# CY8C4248LQI_BL583 register map
File version: 0.1
PSoC 4200 BLE
Registers are 32-bit, read-write, no defined reset value unless marked. A register's access mark holds for its fields unless they carry their own. Offsets are from the block's base; lines under a group give offsets from that group; [hi:lo] are bit positions; {n}, {i} and the like mark numbered series; 'fields as' and 'values as' point back to an identical list; <NAME> marks a mode.

## Memory map
0x00000000 DMAC — DMAC Registers
0x00000000 FanController
0x00000000 FanController_FW_PWM1
0x00000000 FanController_FW_PWM3
0x00000000 FanController_FW_PWM2
0x00000000 FanController_FW_PWM4
0x00000000 UART — Serial Communication Block
0x00000000 Control_Rotation

## FanController
Base 0x00000000
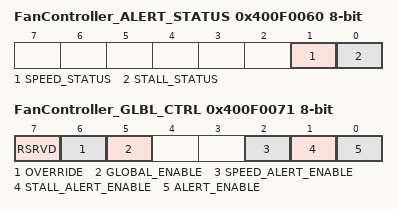
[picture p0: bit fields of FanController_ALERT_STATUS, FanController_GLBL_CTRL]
0x400F0060 FanController_ALERT_STATUS 8-bit — Alert Status Register
  [1] SPEED_STATUS ro — Speed status for all Fans
    0=NO_SPEED_ERROR (No speed error occurred); 1=SPEED_ERROR (Speed error is occurred)
  [0] STALL_STATUS ro — Stall status for all Fans
    0=NO_STALL (No stall occurred); 1=STALL (Stall is occurred)
0x400F0071 FanController_GLBL_CTRL 8-bit — Global Control Register
  [7] RSRVD ro — Reserved
  [6] OVERRIDE — HW mode override bit
    0=OVRD_DISABLED (HW control not overrided); 1=OVRD_ENABLED (HW control overrided)
  [5] GLOBAL_ENABLE — Global enable signal for the component
    0=COMP_DISABLED (Component disabled); 1=COMP_ENABLED (Component is enabled)
  [2] SPEED_ALERT_ENABLE — Speed alert enable signal
    0=SPEED_ALRT_DIS (Generation of speed alert is disabled); 1=SPEED_ALRT_EN (Generation of speed alert is enabled)
  [1] STALL_ALERT_ENABLE — Stall alert enable signal
    0=STALL_ALRT_DIS (Generation of stall alert is disabled); 1=STALL_ALRT_EN (Generation of stall alert is enabled)
  [0] ALERT_ENABLE — Global alert enable signal
    0=ALERTS_DIS (Generation of all alerts is disabled); 1=ALERTS_EN (Generation of alerts is enabled)

## FanController_FW_PWM1
Base 0x00000000; alternate view of FanController
0x40200148 COUNTER — Current counter value
0x4020014C CC — Compare / capture value
0x40200150 CC_BUF — Compare / capture buffer value
0x40200154 PERIOD — Period value
0x40200158 PERIOD_BUF — Period buffer value

## FanController_FW_PWM3
Base 0x00000000; alternate view of FanController
0x40200188 COUNTER — Current counter value
0x4020018C CC — Compare / capture value
0x40200190 CC_BUF — Compare / capture buffer value
0x40200194 PERIOD — Period value
0x40200198 PERIOD_BUF — Period buffer value

## FanController_FW_PWM2
Base 0x00000000; alternate view of FanController
0x402001C8 COUNTER — Current counter value
0x402001CC CC — Compare / capture value
0x402001D0 CC_BUF — Compare / capture buffer value
0x402001D4 PERIOD — Period value
0x402001D8 PERIOD_BUF — Period buffer value

## FanController_FW_PWM4
Base 0x00000000; alternate view of FanController
0x40200108 COUNTER — Current counter value
0x4020010C CC — Compare / capture value
0x40200110 CC_BUF — Compare / capture buffer value
0x40200114 PERIOD — Period value
0x40200118 PERIOD_BUF — Period buffer value

## Control_Rotation
Base 0x00000000
0x400F0070 Control_Rotation_CONTROL_REG 8-bit
